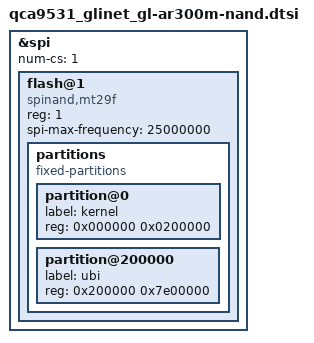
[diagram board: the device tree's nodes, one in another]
/dts-v1/;

#include "qca9531_glinet_gl-ar300m.dtsi"

&spi {
	num-cs = <1>;

	flash@1 {
		compatible = "spinand,mt29f";
		reg = <1>;
		spi-max-frequency = <25000000>;

		partitions {
			compatible = "fixed-partitions";
			#address-cells = <1>;
			#size-cells = <1>;

			partition@0 {
				label = "kernel";
				reg = <0x000000 0x0200000>;
			};

			partition@200000 {
				label = "ubi";
				reg = <0x200000 0x7e00000>;
			};
		};
	};
};
